# cslr_psc register map
Vendor: Texas Instruments
Peripheral module from a debugger description file.
Registers are 32-bit, access not given, reset 0x0 unless marked. A register's access mark holds for its fields unless they carry their own. Offsets are as the file gives them; lines under a group give offsets from that group; [hi:lo] are bit positions; {n}, {i} and the like mark numbered series; 'fields as' and 'values as' point back to an identical list; <NAME> marks a mode.

## PSC — Power and Sleep Controller
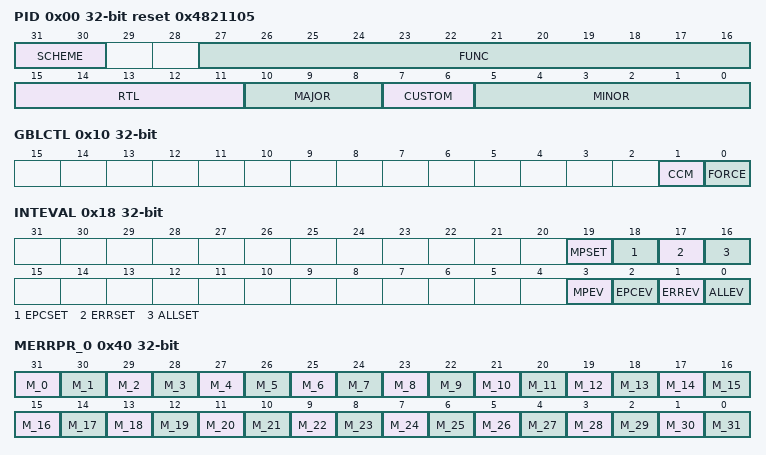
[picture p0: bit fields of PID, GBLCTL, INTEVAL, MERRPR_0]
0x00 PID reset 0x4821105 (reset mask 0x3FFFFFFF) — Peripheral Identification Register
  [31:30] SCHEME ro — Used to distinguish between old scheme and current. Spare bit to encode future schemes
  [27:16] FUNC ro — Indicating a software compatible module family. If there is no level of software compatibility a new ID should be assigned
  [15:11] RTL ro — RTL Version. Must be easily ECO'able or controlled during fabrication. Ideally through a top level metal maskor e_fuse. Start with 0 for PSC1.0, 1 for PSC2.0
  [10:8] MAJOR ro — Major Revision
  [7:6] CUSTOM ro — Indicates a Special Version for a particular device. Consequence of use may avoid use of standard CSL/Drivers. 0 if non_custom
  [5:0] MINOR ro — Minor Revision
0x10 GBLCTL — Global Control register
  [1] CCM rw — PSC MMR Control
  [0] FORCE rw — Force mode bit. When set, the PSC simplifies the "check" performed so that the module or domain can quicklyadvance to the next state without waiting for all conditions to be true
0x14 GBLSTAT — Global Status register
  [0] GBLTRANS ro — PSC Global Transition Status
0x18 INTEVAL — Interrupt Evaluation Register
  [19] MPSET wo — Memory Protection Interrupt Set
  [18] EPCSET wo — External Power Control Interrupt Set
  [17] ERRSET wo — Error Interrupt Set
  [16] ALLSET wo — Combined Interrupt Set
  [3] MPEV wo — Re_evaluate Memory Protection Interrupt
  [2] EPCEV wo — External Power Control Interrupt
  [1] ERREV wo — Re_evaluate Error Interrupt
  [0] ALLEV wo — Re_evaluate Combined PSC Interrupt
0x40 MERRPR_0 ro — Module Error Pending Registers(MERRPR_0 for modules 0 _ 31 and MERRPR_0 for modules 32 _ 63 )
  [31-n] M_{n} (n=0..31) — Module n Error Condition, where n = 0 to 31
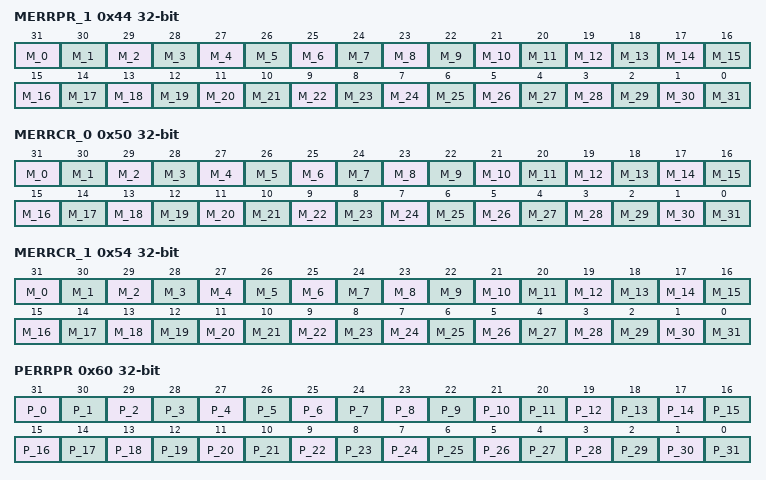
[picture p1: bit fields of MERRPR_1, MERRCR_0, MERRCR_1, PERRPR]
0x44 MERRPR_1 ro — Module Error Pending Registers(MERRPR_1 for modules 0 _ 31 and MERRPR_1 for modules 32 _ 63 )
  [31-n] M_{n} (n=0..31) — Module n Error Condition, where n = 0 to 31
0x50 MERRCR_0 wo — Module Error Clear Registers(MERRCR_0 for modules 0 _ 31 and MERRCR_0 for modules 32 _ 63 )
  [31-n] M_{n} (n=0..31) — Write of '1' to bit n causes Module Error Pending Register (MERRPR) bit n to be cleared, and the module's relevant Module Status register (MDSTAT) fieldsto be cleared, where n = 0 to 31
0x54 MERRCR_1 wo — Module Error Clear Registers(MERRCR_1 for modules 0 _ 31 and MERRCR_1 for modules 32 _ 63 )
  fields as MERRCR_0
0x60 PERRPR ro — Power Domain Error Pending Register
  [31-n] P_{n} (n=0..31) — Power Domain m Error Condition, m = 0 to 31
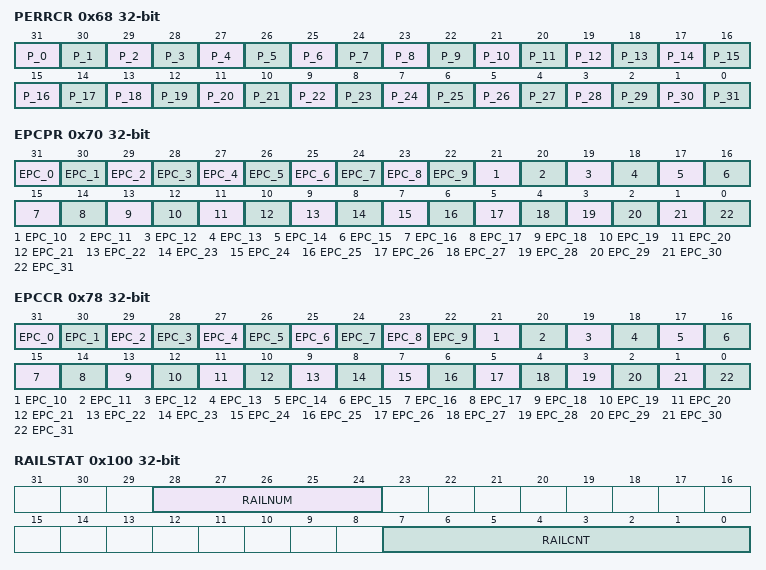
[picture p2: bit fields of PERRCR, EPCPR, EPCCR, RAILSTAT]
0x68 PERRCR wo — Power Domain Error Clear Register
  [31-n] P_{n} (n=0..31) — Write of '1' to bit n causes Power Domain Error Pending Register (PERRPR) bit n to be cleared, and the domain's relevant Power Domain Status Register (PDSTAT) fields to be cleared, n = 0 to 31
0x70 EPCPR ro — External Power Control Pending Register
  [31-n] EPC_{n} (n=0..31) — External Power Control Intervention Request for Power Domain n, where n = 0 to 31
0x78 EPCCR wo — External Power Control Clear Register
  [31-n] EPC_{n} (n=0..31) — Write of '1' to bit n causes External Power Control Pending Register bit n to be cleared, n = 0 to 31
0x100 RAILSTAT — Power Rail Status Register
  [28:24] RAILNUM ro — Indicates Current Rail Requestor being processed by GPSC
  [7:0] RAILCNT ro — Indicates the current rail counter value
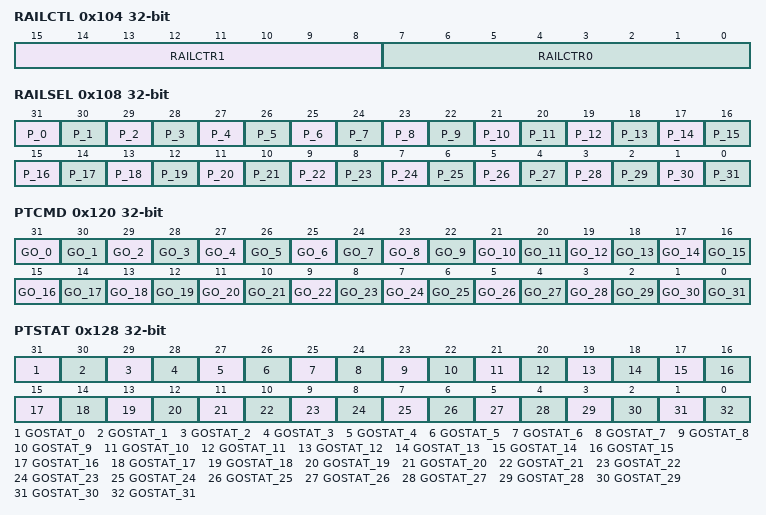
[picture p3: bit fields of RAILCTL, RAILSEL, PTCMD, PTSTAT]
0x104 RAILCTL — Power Rail Counter Control Register
  [15:8] RAILCTR1 rw — Rail Counter Value 1
  [7:0] RAILCTR0 rw — Rail Counter Value 0
0x108 RAILSEL rw — Power Rail Counter Select Register
  [31-n] P_{n} (n=0..31) — Rail Counter Select for Power Domain n, n = 0 to 31. An AlwaysON domain (ALWAYSON parameter = 1) ignores the rail counter selection it should always count 0
0x120 PTCMD wo — Power Domain Transition Command Register
  [31-n] GO_{n} (n=0..31) — Power Domain n GO Transition, n = 0 to 31
0x128 PTSTAT ro — Power Domain Transition Status Register
  [31-n] GOSTAT_{n} (n=0..31) — Power Domain n Transition Command Status, n = 0 to 31
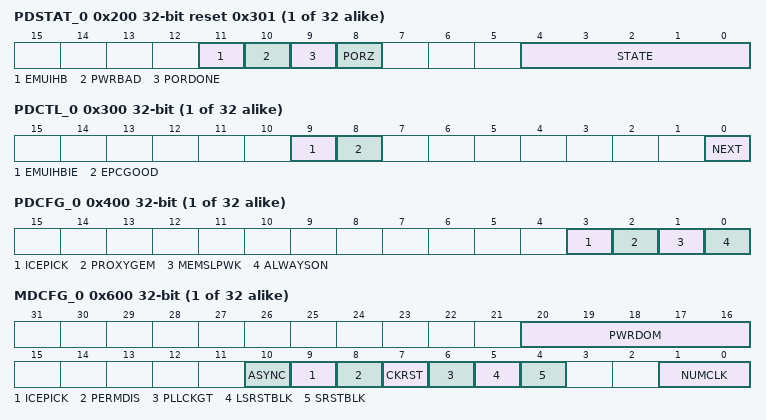
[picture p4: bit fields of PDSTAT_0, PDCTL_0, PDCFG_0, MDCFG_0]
{0x200+4i} PDSTAT_{i} reset 0x301 (i=0..31) — Power Domain Status Registers (0 to 31)
  [11] EMUIHB ro — Emulation Alters Domain State _ Inhibits Off or Forces ON
  [10] PWRBAD ro — Power Bad Error
  [9] PORDONE ro — POR Done Input status
  [8] PORZ — PORz output actual status
  [4:0] STATE ro — Current Power Domain State
{0x300+4i} PDCTL_{i} (i=0..31) — Power Domain Control Registers (0 to 31)
  [9] EMUIHBIE rw — Emulation Alters Domain State
  [8] EPCGOOD rw — External Power Control Power Good Indication
  [0] NEXT rw — User_Desired Next Power Domain State
{0x400+4i} PDCFG_{i} (reset mask 0xFFFFFFF0) (i=0..31) — Power Domain Configuration Registers (0 _ 31)
  [3] ICEPICK ro — IcePick Support
  [2] PROXYGEM ro — Proxy GEM Domain
  [1] MEMSLPWK ro — Memory Sleep/Wake Power Domain
  [0] ALWAYSON ro — AlwaysON Power Domain
{0x600+4i} MDCFG_{i} (i=0..31) — Module Configuration Registers (0 _ 31)
  [20:16] PWRDOM ro — Power Domain Indicates which power domain this module belongs to (0 to 31)
  [10] ASYNC ro — Async LPSC
  [9] ICEPICK ro — IcePick Support
  [8] PERMDIS ro — Permanently Disable
  [7] CKRST ro — Modclk During MSM reset source assert
  [6] PLLCKGT ro — PLL Clock Gate
  [5] LSRSTBLK ro — LRST Soft Reset Block
  [4] SRSTBLK ro — Soft Reset Block
  [1:0] NUMCLK ro — Number of modclks supported on LPSC
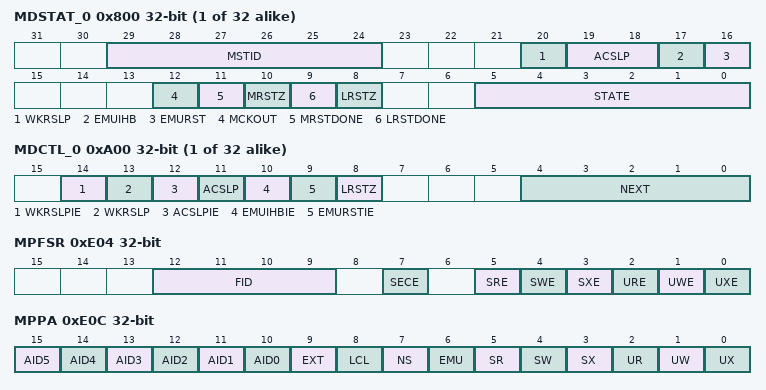
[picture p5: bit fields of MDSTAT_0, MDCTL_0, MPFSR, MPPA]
{0x800+4i} MDSTAT_{i} (i=0..31) — Module Status Registers (0 _ 31)
  [29:24] MSTID ro — Master ID
  [20] WKRSLP ro — Wakeup Request to Module in Sleep Detected
  [19:18] ACSLP ro — Non_emulation access to Module in Sleep Occured
  [17] EMUIHB ro — Emulation Alters Module State
  [16] EMURST ro — Emulation Alters Reset (lrst or mrst) to Module
  [12] MCKOUT ro — Actual modclk output to module
  [11] MRSTDONE ro — Module reset initialization done status
  [10] MRSTZ ro — Module reset actual status
  [9] LRSTDONE ro — Module local reset initialization done status
  [8] LRSTZ ro — Module local reset actual status
  [5:0] STATE ro — These bits indicate the current module state
{0xA00+4i} MDCTL_{i} (i=0..31) — Module Control Registers (0 _ 31)
  [14] WKRSLPIE rw — Wakeup Request to module in sleep Error Enable
  [13] WKRSLP rw — Wakeup Request to Module in Sleep will cause this action
  [12] ACSLPIE rw — Non_Emulation Access to module in sleep Error Enable
  [11] ACSLP rw — Non_Emulation access to module in Sleep will cause this action
  [10] EMUIHBIE rw — Emulation Alters Module State
  [9] EMURSTIE rw — Emulation Alter Reset Interrupt Enable
  [8] LRSTZ rw — Module local reset control (only applicable to some modulese.g. GEM, BCG EMIF)
  [4:0] NEXT rw — Module Next State
0xE00 MPFAR ro — Memory Protection Fault Address Register
  [31:0] FADDR — Memory Protection Fault Address Captures the faulting address when a memory protection violation is detected. This register can only be cleared via MPFCR.MPFCLR.
0xE04 MPFSR — Memory Protection Fault Status Register
  [12:9] FID ro — Faulted ID
  [7] SECE ro — Secure Access Error
  [5] SRE ro — Supervisor Read Error
  [4] SWE ro — Supervisor Write Error
  [3] SXE ro — Supervisor Execute Error. This bit is hard_wired to 0 to indicate no Supervisor Execute Error
  [2] URE ro — User Read Error
  [1] UWE ro — User Write Error
  [0] UXE ro — User Execute Error. This bit is hard_wired to 0 to indicate no User Execute Error
0xE08 MPFCR — Memory Protection Fault Command Register
  [0] MPFCLR wo — Set to Clear Fault
0xE0C MPPA — Memory Protection Page Attribute Register
  [15] AID5 rw — Controls access from ID = 5.
  [14] AID4 rw — Controls access from ID = 4.
  [13] AID3 rw — Controls access from ID = 3.
  [12] AID2 rw — Controls access from ID =2.
  [11] AID1 rw — Controls access from ID = 1.
  [10] AID0 rw — Controls access from ID = 0.
  [9] EXT rw — Controls ID >=6.
  [8] LCL ro — Local Access Permission
  [7] NS ro — Secure Access Permission
  [6] EMU ro — Emulation Security Permission
  [5] SR rw — Supervisor Read Permission
  [4] SW rw — Supervisor Write Permission
  [3] SX ro — Supervisor Execute Permission
  [2] UR rw — User Read Permission
  [1] UW rw — User Write Permission
  [0] UX ro — User Execute Permission
